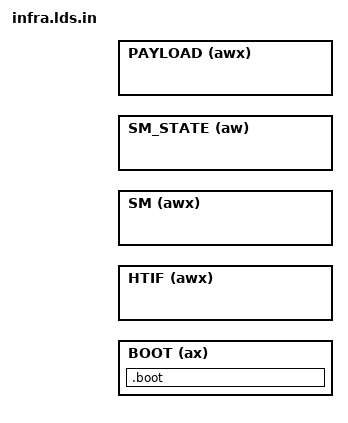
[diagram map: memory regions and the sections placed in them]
#include <parameters.h>

OUTPUT_ARCH( "riscv" )
ENTRY( sm_entry )

MEMORY
{
  BOOT (ax) :      ORIGIN = BOOT_ADDR,       LENGTH = BOOT_MAXLEN
  HTIF (awx)   :  ORIGIN = HTIF_BASE,        LENGTH = HTIF_LEN
  SM (awx) :       ORIGIN = SM_ADDR,         LENGTH = SM_LEN
  SM_STATE (aw) :  ORIGIN = SM_STATE_ADDR,   LENGTH = SM_STATE_LEN
  PAYLOAD (awx) :  ORIGIN = UNTRUSTED_ENTRY, LENGTH = PAYLOAD_MAXLEN
}

SECTIONS
{
  . = ORIGIN(BOOT);
  .boot : {
    PROVIDE( boot_entry = . );
    *(.boot.text.entry)
    *(.boot.*)
    *(.boot)
    . = ALIGN(0x8);
    _device_tree = .;
  } > BOOT =0x0
}

SECTIONS
{
  . = ORIGIN(HTIF);
  .htif ALIGN(0x1000) : {
    PROVIDE( __htif_base = . );
    *(.htif.tohost)
    *(.htif.fromhost)
    *(.htif.*)
    *(.htif)
  } > HTIF =0x0
}

SECTIONS
{
  . = ORIGIN(SM);
  .sm : {
    PROVIDE( sm_entry = . );
    *(.sm) /* Your payload goes here */
  } > SM =0x0
}

SECTIONS
{
  . = ORIGIN(SM_STATE);
  .sm.state : {
    *(.sm.state) /* Your payload goes here */
  } > SM_STATE =0x0
}

SECTIONS
{
  . = ORIGIN(PAYLOAD);
  .text : {
    PROVIDE( payload_entry = . );
    *(.text.entry)
    *(.text.*)
    *(.text)
  } > PAYLOAD =0x0

  .data ALIGN(0x1000) : {
    *(.data.*)
    *(.data)
  } > PAYLOAD =0x0

  .bss ALIGN(0x1000) : {
    *(.bss.*)
    *(.bss)
  } > PAYLOAD =0x0

  .rodata ALIGN(0x1000) : {
    *(.rodata.*)
    *(.rodata)
  } > PAYLOAD =0x0

  .enclave ALIGN(0x1000): {
    *(.enclave)
  } > PAYLOAD =0x0

  .region1 ALIGN(0x2000000) (NOLOAD) : { /* Align to the *next* 32MB boundary */
    PROVIDE( region1 = . );
    BYTE(1)
  } > PAYLOAD =0x0

  .region2 ALIGN(0x2000000) (NOLOAD) : { /* Align to the *next* 32MB boundary */
    PROVIDE( region2 = . );
    BYTE(1)
  } > PAYLOAD =0x0

  .region3 ALIGN(0x2000000) (NOLOAD) : { /* Align to the *next* 32MB boundary */
    PROVIDE( region3 = . );
    BYTE(1)
  } > PAYLOAD =0x0
  
  . = IDPT_BASE;
  .idpt IDPT_BASE : {
    *(.idpt)
  } > PAYLOAD =0x0
}
